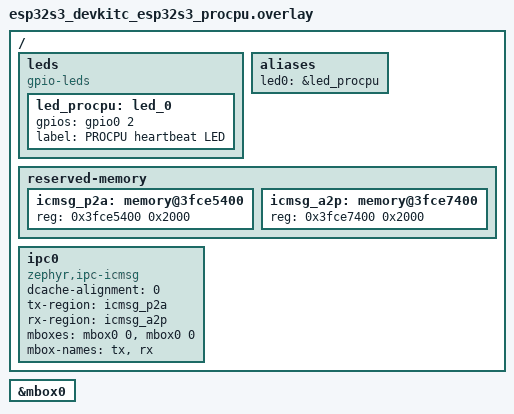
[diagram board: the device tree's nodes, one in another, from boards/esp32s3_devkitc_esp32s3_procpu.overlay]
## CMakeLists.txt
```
cmake_minimum_required(VERSION 3.20.0)

find_package(Zephyr REQUIRED HINTS $ENV{ZEPHYR_BASE})
project(04_ipc_service_icmsg_procpu)

target_sources(app PRIVATE src/main.c)
```

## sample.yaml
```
sample:
  name: 04_ipc_service_icmsg_lab
  description: >
    Lab 04 - Reimplements Lab 03's "keep an incrementing sequence number in
    sync between procpu and appcpu" experiment using Zephyr's IPC Service
    framework (icmsg backend) instead of raw MBOX + a hand-rolled shared
    struct. procpu sends seq numbers every 200ms and appcpu echoes each one
    straight back; unlike Lab 03's single shared-memory slot, icmsg's queued
    ring buffer means every single value is expected to arrive back in order
    with none skipped.

common:
  tags:
    - dual-core
    - ipc
    - ipc-service
    - icmsg
  platform_allow:
    - esp32s3_devkitc/esp32s3/procpu

tests:
  sample.dual_core.ipc_service_icmsg:
    build_only: true
```

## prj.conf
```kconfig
# 04_IPC_SERVICE_ICMSG_LAB - core0 (procpu) image
#
# This lab's real teaching content: replacing Lab 03's raw MBOX + hand-rolled
# shared struct with Zephyr's IPC Service framework (icmsg backend). See the
# doc for the full devicetree/API design and why this fixes the data-loss
# problem Lab 03 deliberately demonstrated.
#
# CONFIG_IPC_SERVICE_BACKEND_ICMSG defaults to y automatically once the
# devicetree has an enabled "zephyr,ipc-icmsg" node (see lab/boards/*.overlay),
# so it does not need to be set explicitly here - CONFIG_MBOX is still needed
# because icmsg uses MBOX internally as its notification "kick".
#
# NOTE: &ipm0 is intentionally left DISABLED - see 02_MBOX_DOORBELL_LAB's doc
# for why only one of ipm0/mbox0 is ever enabled per lab.

CONFIG_GPIO=y
CONFIG_MBOX=y
CONFIG_IPC_SERVICE=y

CONFIG_LOG=y
CONFIG_LOG_MODE_IMMEDIATE=y
```

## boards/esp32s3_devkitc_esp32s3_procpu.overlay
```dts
/*
 * Overlay for 04_IPC_SERVICE_ICMSG_LAB - core0 (procpu) image
 *
 * Reuses this series' GPIO2 "led0" heartbeat LED convention (see Lab 01).
 *
 * Shared memory for the IPC Service icmsg backend:
 *
 * ESP32-S3's SoC devicetree (dts/xtensa/espressif/esp32s3/esp32s3_common.dtsi)
 * already declares TWO adjacent blocks right before the &ipm0/&mbox0
 * register block:
 *
 *   ipmmem0: memory@3fce5000 { compatible = "mmio-sram"; reg = <0x3fce5000 0x400>;  }; (1KB  - used by Lab 02/03)
 *   shm0:    memory@3fce5400 { compatible = "mmio-sram"; reg = <0x3fce5400 0x4000>; }; (16KB - NOT used by any lab yet)
 *
 * "shm0" is a second, separate 16KB block, declared right next to ipmmem0
 * using the exact same pattern - clearly intended by the SoC port as
 * general-purpose dual-core shared memory (its name is literally "shared
 * memory 0"). No existing Zephyr sample currently uses it, but it is
 * declared the same way as ipmmem0, which we have already proven safe to
 * use on real hardware across Labs 02/03. This lab splits shm0's 16KB into
 * two 8KB halves (icmsg_p2a/icmsg_a2p below) for the icmsg backend's tx/rx
 * ring buffers - see the doc for the full reasoning.
 *
 * dcache-alignment is set to 0 (no cache management needed): Labs 02/03
 * already read and wrote this same address range directly via plain
 * `volatile` pointers, with no cache flush/invalidate of any kind, and
 * worked correctly on real hardware - meaning this SRAM range is not
 * behind either core's data cache.
 */

#include <zephyr/dt-bindings/gpio/gpio.h>

/ {
    leds {
        compatible = "gpio-leds";
        led_procpu: led_0 {
            gpios = <&gpio0 2 GPIO_ACTIVE_HIGH>;
            label = "PROCPU heartbeat LED";
        };
    };

    aliases {
        led0 = &led_procpu;
    };

    reserved-memory {
        #address-cells = <1>;
        #size-cells = <1>;

        /* procpu writes here, appcpu reads (procpu -> appcpu) */
        icmsg_p2a: memory@3fce5400 {
            reg = <0x3fce5400 0x2000>;
        };

        /* appcpu writes here, procpu reads (appcpu -> procpu) */
        icmsg_a2p: memory@3fce7400 {
            reg = <0x3fce7400 0x2000>;
        };
    };

    ipc0: ipc0 {
        compatible = "zephyr,ipc-icmsg";
        dcache-alignment = <0>;
        tx-region = <&icmsg_p2a>;
        rx-region = <&icmsg_a2p>;
        mboxes = <&mbox0 0>, <&mbox0 0>;
        mbox-names = "tx", "rx";
        status = "okay";
    };
};

/*
 * &ipm0 stays disabled here on purpose - only &mbox0 is enabled, per this
 * series' policy (see 02_MBOX_DOORBELL_LAB's doc). The icmsg backend uses
 * &mbox0 internally purely as a "check the ring buffer" kick - actual
 * message bytes travel through icmsg_p2a/icmsg_a2p above, never through
 * &mbox0's own private shared-memory scratch buffer (ipmmem0).
 */
&mbox0 {
    status = "okay";
};
```

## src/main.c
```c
/*
 * main.c - 04_IPC_SERVICE_ICMSG_LAB (core0 / procpu image)
 *
 * Reimplements 03_SHM_RACE_LAB's experiment - keep sending an incrementing
 * sequence number, have appcpu echo it straight back - but this time
 * through Zephyr's IPC Service framework (icmsg backend) instead of raw
 * MBOX + a hand-rolled shared struct. See the doc for why this fixes the
 * data-loss problem Lab 03 deliberately exposed: icmsg's shared memory is
 * a real queued ring buffer (one slot per message), not a single
 * overwritable slot, so no value in between two reads is ever silently
 * lost the way it was in Lab 03.
 */

#include <zephyr/kernel.h>
#include <zephyr/device.h>
#include <zephyr/drivers/gpio.h>
#include <zephyr/ipc/ipc_service.h>
#include <zephyr/logging/log.h>

#include "common.h"

LOG_MODULE_REGISTER(app_procpu, LOG_LEVEL_INF);

static const struct gpio_dt_spec led = GPIO_DT_SPEC_GET(DT_ALIAS(led0), gpios);

#define LED_PERIOD_MS  500
#define SEND_PERIOD_MS 200

K_SEM_DEFINE(bound_sem, 0, 1);

static uint32_t total_sent;
static uint32_t total_received;

static void ep_bound(void *priv)
{
	ARG_UNUSED(priv);

	LOG_INF("endpoint bound");
	k_sem_give(&bound_sem);
}

static void ep_recv(const void *data, size_t len, void *priv)
{
	ARG_UNUSED(priv);

	if (len != sizeof(struct app_msg)) {
		LOG_ERR("unexpected message length %zu", len);
		return;
	}

	const struct app_msg *msg = data;

	total_received++;
	LOG_INF("recv reply seq=%u (total_received=%u, total_sent=%u)",
		msg->seq, total_received, total_sent);
}

static void ep_error(const char *message, void *priv)
{
	ARG_UNUSED(priv);

	LOG_ERR("icmsg error: %s", message);
}

static struct ipc_ept_cfg ep_cfg = {
	.cb = {
		.bound = ep_bound,
		.received = ep_recv,
		.error = ep_error,
	},
};

int main(void)
{
	const struct device *ipc0_instance;
	struct ipc_ept ep;
	int ret;

	LOG_INF("04_IPC_SERVICE_ICMSG_LAB (core0/procpu) starting");

	if (!gpio_is_ready_dt(&led)) {
		LOG_ERR("led gpio not ready");
		return -1;
	}

	if (gpio_pin_configure_dt(&led, GPIO_OUTPUT_INACTIVE)) {
		LOG_ERR("failed to configure led");
		return -1;
	}

	ipc0_instance = DEVICE_DT_GET(DT_NODELABEL(ipc0));

	ret = ipc_service_open_instance(ipc0_instance);
	if (ret < 0 && ret != -EALREADY) {
		LOG_ERR("ipc_service_open_instance() failed (%d)", ret);
		return ret;
	}

	ret = ipc_service_register_endpoint(ipc0_instance, &ep, &ep_cfg);
	if (ret < 0) {
		LOG_ERR("ipc_service_register_endpoint() failed (%d)", ret);
		return ret;
	}

	LOG_INF("waiting for endpoint to bind...");
	k_sem_take(&bound_sem, K_FOREVER);

	bool led_state = false;
	int64_t next_led_toggle = k_uptime_get() + LED_PERIOD_MS;
	int64_t next_send = k_uptime_get() + SEND_PERIOD_MS;
	uint32_t pending_seq = 0; /* seq value awaiting a successful send, 0 = none pending */

	while (1) {
		int64_t now = k_uptime_get();

		if (now >= next_led_toggle) {
			led_state = !led_state;
			gpio_pin_set_dt(&led, led_state);
			next_led_toggle = now + LED_PERIOD_MS;
		}

		if (now >= next_send) {
			uint32_t seq = pending_seq ? pending_seq : (total_sent + 1);
			struct app_msg msg = { .seq = seq };

			ret = ipc_service_send(&ep, &msg, sizeof(msg));
			if (ret == -ENOMEM) {
				/*
				 * icmsg's ring buffer is momentarily full - back off
				 * and retry the SAME seq value next tick instead of
				 * moving on to the next one, so we never silently
				 * skip a value the way Lab 03's single shared slot
				 * could.
				 */
				LOG_WRN("send buffer full, retrying seq=%u", seq);
				pending_seq = seq;
			} else if (ret < 0) {
				LOG_ERR("ipc_service_send() failed (%d)", ret);
				pending_seq = seq;
			} else {
				total_sent = seq;
				pending_seq = 0;
				LOG_INF("sent seq=%u (total_sent=%u)", seq, total_sent);
			}

			next_send = now + SEND_PERIOD_MS;
		}

		k_msleep(10);
	}

	return 0;
}
```

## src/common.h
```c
/*
 * common.h - 04_IPC_SERVICE_ICMSG_LAB
 *
 * The single message type exchanged over the icmsg endpoint in both
 * directions. This file is intentionally duplicated byte-for-byte between
 * src/ and remote/src/ - see shared_mem.h in 03_SHM_RACE_LAB for why
 * (procpu and appcpu are two completely separate Zephyr applications). If
 * you edit this file, edit both copies.
 */

#ifndef COMMON_H_
#define COMMON_H_

#include <stdint.h>

struct app_msg {
	uint32_t seq;
};

#endif /* COMMON_H_ */
```
